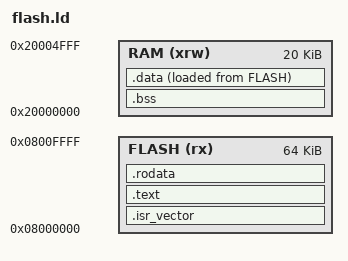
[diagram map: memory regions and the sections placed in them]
/*
*****************************************************************************
**
**  File        : STM32F103X6_FLASH.ld
**
**  Abstract    : Linker script for STM32F103x6 Device with
**                32KByte FLASH, 10KByte RAM
**
**                Set heap size, stack size and stack location according
**                to application requirements.
**
**                Set memory bank area and size if external memory is used.
**
**  Target      : STMicroelectronics STM32
**
**  Environment : Atollic TrueSTUDIO(R)
**
**  Distribution: The file is distributed “as is,” without any warranty
**                of any kind.
**
**  (c)Copyright Atollic AB.
**  You may use this file as-is or modify it according to the needs of your
**  project. This file may only be built (assembled or compiled and linked)
**  using the Atollic TrueSTUDIO(R) product. The use of this file together
**  with other tools than Atollic TrueSTUDIO(R) is not permitted.
**
*****************************************************************************
*/

/* Entry Point */
ENTRY(Reset_Handler)



/* Highest address of the user mode stack */
_estack = 0x20004FFF;    /* end of RAM */



/* Specify the memory areas */
MEMORY
{
FLASH (rx)      : ORIGIN = 0x08000000, LENGTH = 64K
RAM (xrw)       : ORIGIN = 0x20000000, LENGTH = 20K
}



/* Define output sections */
SECTIONS
{



  /* The startup code goes first into FLASH */
  .isr_vector :
  {
    . = ALIGN(4);
    KEEP(*(.isr_vector)) /* Startup code */
    . = ALIGN(4);
  } >FLASH



  /* The program code and other data goes into FLASH */
  .text :
  {
    . = ALIGN(4);
    *(.text)           /* .text sections (code) */
    *(.text*)          /* .text* sections (code) */
    . = ALIGN(4);
  } >FLASH



  /* Constant data goes into FLASH */
  .rodata :
  {
    . = ALIGN(4);
    *(.rodata)         /* .rodata sections (constants, strings, etc.) */
    *(.rodata*)        /* .rodata* sections (constants, strings, etc.) */
    . = ALIGN(4);
  } >FLASH

/* ARM UNWINDING SECTION
  .ARM.extab   : { *(.ARM.extab* .gnu.linkonce.armextab.*) } >FLASH
  .ARM : {
    __exidx_start = .;
    *(.ARM.exidx*)
    __exidx_end = .;
  } >FLASH
*/


  /* Uninitialized data section */
  .bss (NOLOAD):
  {
		. = ALIGN(4);
    _sbss = .;         /* define a global symbol at bss start */

    *(.bss)
    *(.bss*)
    *(COMMON)

    . = ALIGN(4);
    _ebss = .;         /* define a global symbol at bss end */
  } >RAM



  /* used by the startup to initialize data */
  _sidata = LOADADDR(.data);

  .data : 
  {
    . = ALIGN(4);
    _sdata = .;        /* create a global symbol at data start */

    *(.data)           /* .data sections */
    *(.data*)          /* .data* sections */

    . = ALIGN(4);
    _edata = .;        /* define a global symbol at data end */
  } >RAM AT> FLASH

  

  /* Remove information from the standard libraries */
  /DISCARD/ :
  {
    libc.a ( * )
    libm.a ( * )
    libgcc.a ( * )
  }

  .ARM.attributes 0 : { *(.ARM.attributes) }
}
